# STM32G534 register map
File version: 2.0.0
CPU: CM33 r0p4, little endian, MPU, FPU, 4 interrupt priority bits
Registers are 32-bit, read-write, reset 0x0 unless marked. A register's access mark holds for its fields unless they carry their own. Offsets are from the block's base; [hi:lo] are bit positions; {n}, {i} and the like mark numbered series; 'fields as' and 'values as' point back to an identical list.

## DTS — DTS address block description
Base 0x40008C00
Same registers: DTS_S 0x50008C00
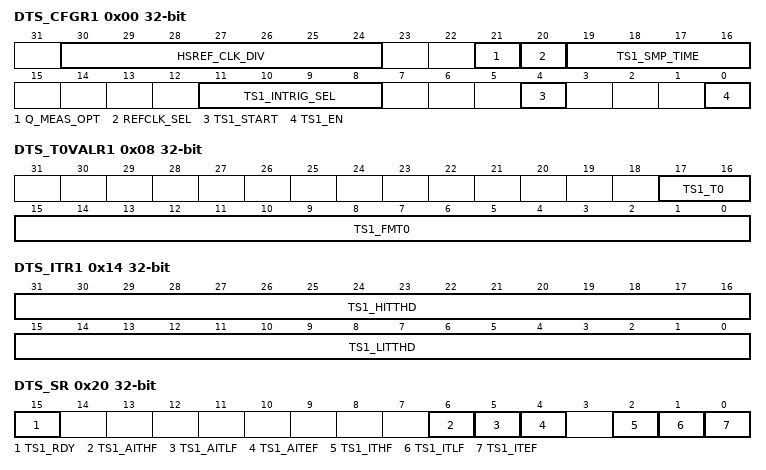
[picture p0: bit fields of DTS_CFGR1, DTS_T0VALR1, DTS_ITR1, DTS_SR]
0x00 DTS_CFGR1 — Temperature sensor configuration register 1
  [30:24] HSREF_CLK_DIV — High speed clock division ratio These bits are set and cleared by software. They can be used to define the division ratio for the main clock in order to obtain the internal frequency lower than 1 MHz required for the calibration. They are applicable only for calibration when PCLK is selected as reference clock (REFCLK_SEL=0). ...
    0=No divider; 1=No divider; 2=1/2 division ratio; 127=1/127 division ratio
  [21] Q_MEAS_OPT — Quick measurement option bit This bit is set and cleared by software. It is used to increase the measurement speed by suppressing the calibration step. It is effective only when the LSE clock is used as reference clock (REFCLK_SEL=1).
    0=Measurement with calibration; 1=Measurement without calibration
  [20] REFCLK_SEL — Reference clock selection bit This bit is set and cleared by software. It indicates whether the reference clock is the high speed clock (PCLK) or the low speed clock (LSE).
    0=High speed reference clock (PCLK); 1=Low speed reference clock (LSE)
  [19:16] TS1_SMP_TIME — Sampling time for temperature sensor 1 These bits allow increasing the sampling time to improve measurement precision. When the PCLK clock is selected as reference clock (REFCLK_SEL = 0), the measurement will be performed at TS1_SMP_TIME period of CLK_PTAT. When the LSE is selected as reference clock (REFCLK_SEL =1), the measurement will be performed at TS1_SMP_TIME period of LSE.
  [11:8] TS1_INTRIG_SEL — Input trigger selection bit for temperature sensor 1 These bits are set and cleared by software. They select which input triggers a temperature measurement. Refer to Section 19.3.10: Trigger input.
  [4] TS1_START — Start frequency measurement on temperature sensor 1 This bit is set and cleared by software.
    0=No software trigger; 1=Software trigger for a frequency measurement. (only if TS1 is ready).
  [0] TS1_EN — Temperature sensor 1 enable bit This bit is set and cleared by software. Note: Once enabled, the temperature sensor is active after a specific delay time. The TS1_RDY flag will be set when the sensor is ready.
    0=Temperature sensor 1 disabled; 1=Temperature sensor 1 enabled
0x08 DTS_T0VALR1 ro (reset mask 0xFFF00000) — Temperature sensor T0 value register 1
  [17:16] TS1_T0 — Engineering value of the T0 temperature for temperature sensor 1. Others: Reserved, must not be used.
    0=30 degree C; 1=130 degree C
  [15:0] TS1_FMT0 — Engineering value of the frequency measured at T0 for temperature sensor 1 This value is expressed in 0.1 kHz.
0x10 DTS_RAMPVALR ro reset not defined — Temperature sensor ramp value register
  [15:0] TS1_RAMP_COEFF — Engineering value of the ramp coefficient for the temperature sensor 1. This value is expressed in Hz/ C.
0x14 DTS_ITR1 — Temperature sensor interrupt threshold register 1
  [31:16] TS1_HITTHD — High interrupt threshold for temperature sensor 1 These bits are set and cleared by software. They indicate the highest value than can be reached before raising an interrupt signal.
  [15:0] TS1_LITTHD — Low interrupt threshold for temperature sensor 1 These bits are set and cleared by software. They indicate the lowest value than can be reached before raising an interrupt signal.
0x1C DTS_DR — Temperature sensor data register
  [15:0] TS1_MFREQ — Value of the counter output value for temperature sensor 1
0x20 DTS_SR ro — Temperature sensor status register
  [15] TS1_RDY — Temperature sensor 1 ready flag This bit is set and reset by hardware. It indicates that a measurement is ongoing.
    0=Temperature sensor 1 busy; 1=Temperature sensor 1 ready
  [6] TS1_AITHF — Asynchronous interrupt flag for high threshold on temperature sensor 1 This bit is set by hardware when the high threshold is reached. It is cleared by software by writing 1 to the TS1_CAITHF bit in the DTS_ICIFR register. Note: This bit is active only when the TS1_AITHFEN bit is set
    0=High threshold not reached on temperature sensor 1; 1=High threshold reached on temperature sensor 1
  [5] TS1_AITLF — Asynchronous interrupt flag for low threshold on temperature sensor 1 This bit is set by hardware when the low threshold is reached. It is cleared by software by writing 1 to the TS1_CAITLF bit in the DTS_ICIFR register. Note: This bit is active only when the TS1_AITLFEN bit is set
    0=Low threshold not reached on temperature sensor 1; 1=Low threshold reached on temperature sensor 1
  [4] TS1_AITEF — Asynchronous interrupt flag for end of measure on temperature sensor 1 This bit is set by hardware when a temperature measure is done. It is cleared by software by writing 1 to the TS1_CAITEF bit in the DTS_ICIFR register. Note: This bit is active only when the TS1_AITEFEN bit is set
    0=End of measure not detected on temperature sensor 1; 1=End of measure detected on temperature sensor 1
  [2] TS1_ITHF — Interrupt flag for high threshold on temperature sensor 1, synchronized on PCLK This bit is set by hardware when the high threshold is set and reached. It is cleared by software by writing 1 to the TS1_CITHF bit in the DTS_ICIFR register. Note: This bit is active only when the TS1_ITHFEN bit is set
    values as TS1_AITHF
  [1] TS1_ITLF — Interrupt flag for low threshold on temperature sensor 1, synchronized on PCLK. This bit is set by hardware when the low threshold is set and reached. It is cleared by software by writing 1 to the TS1_CITLF bit in the DTS_ICIFR register. Note: This bit is active only when the TS1_ITLFEN bit is set
    values as TS1_AITLF
  [0] TS1_ITEF — Interrupt flag for end of measurement on temperature sensor 1, synchronized on PCLK. This bit is set by hardware when a temperature measure is done. It is cleared by software by writing 1 to the TS2_CITEF bit in the DTS_ICIFR register. Note: This bit is active only when the TS1_ITEFEN bit is set
    0=No end of measurement detected on temperature sensor 1; 1=End of measure detected on temperature sensor 1
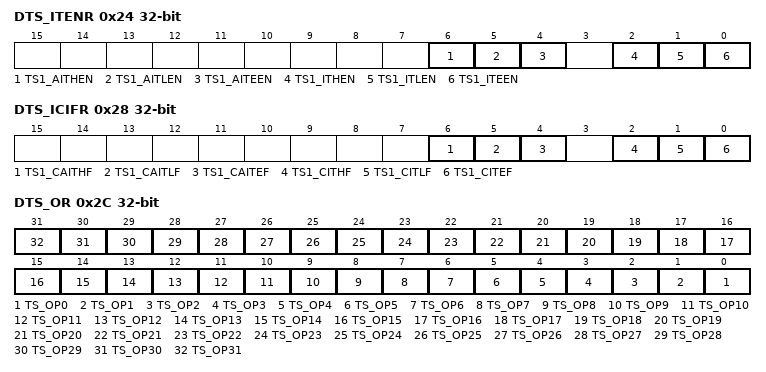
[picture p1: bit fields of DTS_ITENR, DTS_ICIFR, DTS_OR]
0x24 DTS_ITENR — Temperature sensor interrupt enable register
  [6] TS1_AITHEN — Asynchronous interrupt enable flag on high threshold for temperature sensor 1. This bit are set and cleared by software. It enables the asynchronous interrupt when the temperature is above the high threshold (only when REFCLK_SEL= 1'')
    0=Asynchronous interrupt on high threshold disabled for temperature sensor 1; 1=Asynchronous interrupt on high threshold enabled for temperature sensor 1
  [5] TS1_AITLEN — Asynchronous interrupt enable flag for low threshold on temperature sensor 1. This bit are set and cleared by software. It enables the asynchronous interrupt when the temperature is below the low threshold (only when REFCLK_SEL= 1)
    0=Asynchronous interrupt on low threshold disabled for temperature sensor 1; 1=Asynchronous interrupt on low threshold enabled for temperature sensor 1
  [4] TS1_AITEEN — Asynchronous interrupt enable flag for end of measurement on temperature sensor 1 This bit are set and cleared by software. It enables the asynchronous interrupt for end of measurement (only when REFCLK_SEL = 1).
    0=Asynchronous interrupt for end of measurement disabled on temperature sensor 1; 1=Asynchronous interrupt for end of measurement enabled on temperature sensor 1
  [2] TS1_ITHEN — Interrupt enable flag for high threshold on temperature sensor 1, synchronized on PCLK. This bit are set and cleared by software. It enables the interrupt when the measure reaches or is above the high threshold.
    0=Synchronous interrupt for high threshold disabled on temperature sensor 1; 1=Synchronous interrupt for high threshold enabled on temperature sensor 1
  [1] TS1_ITLEN — Interrupt enable flag for low threshold on temperature sensor 1, synchronized on PCLK. This bit are set and cleared by software. It enables the synchronous interrupt when the measure reaches or is below the low threshold.
    0=Synchronous interrupt for low threshold disabled on temperature sensor 1; 1=Synchronous interrupt for low threshold enabled on temperature sensor 1
  [0] TS1_ITEEN — Interrupt enable flag for end of measurement on temperature sensor 1, synchronized on PCLK. This bit are set and cleared by software. It enables the synchronous interrupt for end of measurement.
    0=Synchronous interrupt for end of measurement disabled on temperature sensor 1; 1=Synchronous interrupt for end of measurement enabled on temperature sensor 1
0x28 DTS_ICIFR — Temperature sensor clear interrupt flag register
  [6] TS1_CAITHF — Asynchronous interrupt clear flag for high threshold on temperature sensor 1 Writing 1 to this bit clears the TS1_AITHF flag in the DTS_SR register.
  [5] TS1_CAITLF — Asynchronous interrupt clear flag for low threshold on temperature sensor 1 Writing 1 to this bit clears the TS1_AITLF flag in the DTS_SR register.
  [4] TS1_CAITEF — Write once bit. Clear the asynchronous IT flag for End Of Measure for thermal sensor 1. Writing 1 clears the TS1_AITEF flag of the DTS_SR register.
  [2] TS1_CITHF — Interrupt clear flag for high threshold on temperature sensor 1 Writing this bit to 1 clears the TS1_ITHF flag in the DTS_SR register.
  [1] TS1_CITLF — Interrupt clear flag for low threshold on temperature sensor 1 Writing 1 to this bit clears the TS1_ITLF flag in the DTS_SR register.
  [0] TS1_CITEF — Interrupt clear flag for end of measurement on temperature sensor 1 Writing 1 to this bit clears the TS1_ITEF flag in the DTS_SR register.
0x2C DTS_OR — Temperature sensor option register
  [n] TS_OP{n} (n=0..31) — general purpose option bits
